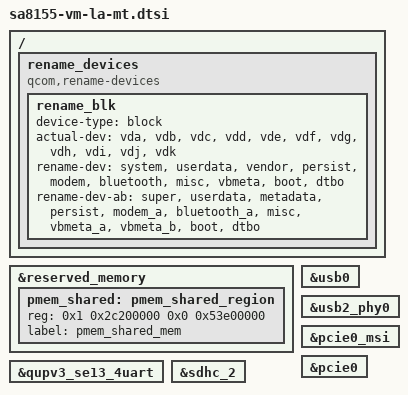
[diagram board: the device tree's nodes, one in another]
&reserved_memory {
	pmem_shared: pmem_shared_region {
		reg = <0x1 0x2c200000 0x0 0x53e00000>;
		label = "pmem_shared_mem";
	};
};

#include "display/quin-vm-display-la.dtsi"

/ {
	rename_devices: rename_devices {
		compatible = "qcom,rename-devices";
		rename_blk: rename_blk {
			device-type = "block";
			actual-dev = "vda", "vdb", "vdc",
					"vdd", "vde", "vdf",
					"vdg", "vdh", "vdi",
					"vdj", "vdk";
			rename-dev = "system", "userdata", "vendor",
					"persist", "modem", "bluetooth",
					"misc", "vbmeta", "boot", "dtbo";
			rename-dev-ab = "super", "userdata", "metadata",
					"persist", "modem_a", "bluetooth_a",
					"misc", "vbmeta_a", "vbmeta_b",
					"boot", "dtbo";
		};
	};

	/delete-node/ cpus;
};

&usb0 {
	status = "ok";
};

&usb2_phy0 {
	status = "ok";
};

&qupv3_se13_4uart {
	status = "ok";
};

&pcie0_msi {
	status = "ok";
};

&pcie0 {
	status = "ok";
};

&sdhc_2 {
	status = "ok";
};
